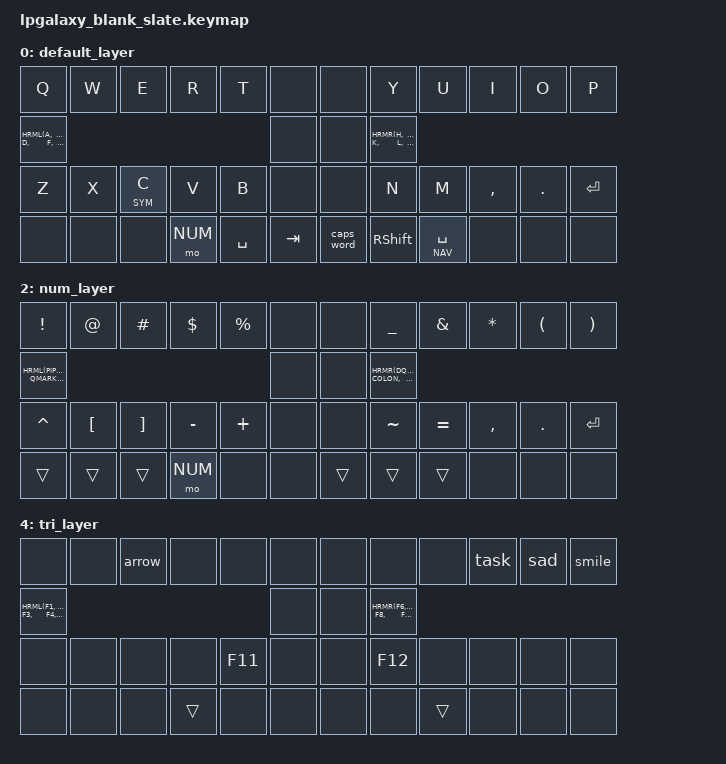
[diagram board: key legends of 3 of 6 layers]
/*
 * Copyright (c) 2022 Pete Johanson
 *
 * SPDX-License-Identifier: MIT
 */

#include <behaviors.dtsi>
#include <dt-bindings/zmk/keys.h>
#include <dt-bindings/zmk/bt.h>
#include <dt-bindings/zmk/outputs.h>
#include <dt-bindings/zmk/pointing.h>
#include "helper.h"

#define DEF 0
#define SYM 1
#define NUM 2
#define NAV 3
#define TRI 4
#define CONF 5

#define XXX &none
#define ___ &trans
#define MEH LC(LA(LSHIFT))

#define QUICK_TAP_MS 175
#define TAPPING_TERM_MS 300
#define REQ_PRIOR_IDLE_MS 200

// Home row mods macro
#define HRML(k1,k2,k3,k4,k5) &hml LSHIFT k1 &hml LGUI k2 &hml LALT k3 &hml LCTRL k4 &hml MEH k5
#define HRMR(k1,k2,k3,k4,k5) &hmr MEH k1 &hmr RCTRL k2  &hmr LALT k3 &hmr RGUI k4 &hmr RSHIFT k5

// Bluetooth
#define BT_SEL_ROW &bt BT_SEL 0 &bt BT_SEL 1 &bt BT_SEL 2 &bt BT_SEL 3
#define BT_SEL_CLR &bt BT_CLR

&caps_word {
    continue-list = <UNDERSCORE MINUS BSPC DOT>;
};

#define KEYS_L 0 1 2 3 4 5 12 13 14 15 16 17 24 25 26 27 28 29   // left-hand keys
#define KEYS_R 6 7 8 9 10 11 18 19 20 21 22 23 30 31 32 33 34 35 // right-hand keys
#define THUMBS 39 40 41 42 43 44           // thumb keys

ZMK_BEHAVIOR(hml, hold_tap,  // left-hand HRMs
    flavor = "balanced";
    tapping-term-ms = <TAPPING_TERM_MS>;
    quick-tap-ms = <QUICK_TAP_MS>;
    require-prior-idle-ms = <REQ_PRIOR_IDLE_MS>;
    hold-trigger-on-release;
    bindings = <&kp>, <&kp>;
    hold-trigger-key-positions = <KEYS_R THUMBS>;
)

ZMK_BEHAVIOR(hmr, hold_tap,  // right-hand HRMs
    flavor = "balanced";
    tapping-term-ms = <TAPPING_TERM_MS>;
    quick-tap-ms = <QUICK_TAP_MS>;
    require-prior-idle-ms = <REQ_PRIOR_IDLE_MS>;
    hold-trigger-on-release;
    bindings = <&kp>, <&kp>;
    hold-trigger-key-positions = <KEYS_L THUMBS>;
)

#undef COMBO_TERM
#define COMBO_TERM 30  // timeout of 40ms (default is 30ms if omitted)
ZMK_COMBO(paswe,        &pasw,          11 12 13, DEF)    // pasw macro on P+A+S
ZMK_COMBO(lockscr,      &kp LG(L),      0 1 2,    DEF)    // Win lock screen by pressing Q W E
ZMK_COMBO(conflayer,    &to CONF,       0 11,     DEF)    // config layer op Q en P
ZMK_COMBO(ctrlspce,     &kp LC(SPACE),  15 20,    DEF)    // runbar op F + J 

// windows sleep macro
ZMK_BEHAVIOR(win_sleep, macro,
    wait-ms = <100>;
    tap-ms = <5>;
    bindings = <&kp LG(X) &kp U &kp S>;
)

ZMK_BEHAVIOR(smile, macro,
    wait-ms = <100>;
    tap-ms = <5>;
    bindings = <&macro_tap &kp COLON &kp MINUS &kp RPAR>;
)

ZMK_BEHAVIOR(pasw, macro,
    wait-ms = <100>;
    tap-ms = <100>;
    bindings = <&macro_tap &kp EXCL &kp P &kp A &kp S &kp W &kp R>;
)
ZMK_BEHAVIOR(sad, macro,
    wait-ms = <100>;
    tap-ms = <5>;
    bindings = <&macro_tap &kp COLON &kp MINUS &kp LPAR>;
)
ZMK_BEHAVIOR(arrow, macro,
    wait-ms = <100>;
    tap-ms = <5>;
    bindings = <&macro_tap &kp MINUS &kp GT>;
)
ZMK_BEHAVIOR(task, macro,
    wait-ms = <100>;
    tap-ms = <5>;
    bindings = <&macro_tap &kp MINUS &kp SPACE &kp LBKT &kp SPACE &kp RBKT &kp SPACE>;
)
ZMK_CONDITIONAL_LAYER (NUM NAV, TRI)

ZMK_LAYER(default_layer,
                &kp Q       &kp W     &kp E      &kp R     &kp T        XXX      XXX        &kp Y       &kp U         &kp I      &kp O      &kp P
                HRML(A,     S,        D,         F,        G)           XXX      XXX        HRMR(H,     J,            K,         L,         BSPC)     
                &kp Z       &kp X     &lt SYM C  &kp V     &kp B        XXX      XXX        &kp N       &kp M         &kp COMMA  &kp DOT    &kp ENTER
                XXX         XXX       XXX        &mo NUM   &kp SPACE    &kp TAB  &caps_word &kp RSHIFT  &lt NAV SPACE XXX        XXX        XXX
)

ZMK_LAYER(sym_layer, 
                ___       ___       ___        ___       ___          XXX      XXX        &kp LBRC    &kp N4        &kp N5     &kp N6     &kp RBRC
                HRML(A,   S,        D,         F,        G)           XXX      XXX        &kp N0      &kp N1        &kp N2     &kp N3     ___
                ___       ___       &lt SYM C  ___       ___          XXX      XXX        &kp DOT     &kp N7        &kp N8     &kp N9     ___
                ___       ___       ___        XXX       ___          XXX      ___        ___         ___           ___        ___        ___
)

ZMK_LAYER(num_layer,
                &kp EXCL    &kp AT    &kp HASH  &kp DOLLAR &kp PERCENT  XXX      XXX       &kp UNDER   &kp AMPS      &kp STAR   &kp LPAR   &kp RPAR
                HRML(PIPE,  BSLH,     FSLH,     QMARK,     GRAVE)       XXX      XXX       HRMR(DQT,   SQT,          COLON,     SEMI,      BSPC)
                &kp CARET   &kp LBKT  &kp RBKT  &kp MINUS  &kp PLUS     XXX      XXX       &kp TILDE   &kp EQUAL     &kp COMMA  &kp DOT    &kp ENTER
                ___         ___       ___       &mo NUM    XXX          XXX      ___       ___         ___           XXX        XXX        XXX
)

ZMK_LAYER(nav_layer,
   	 	        &kp ESC     XXX       XXX       XXX        XXX          XXX      XXX       XXX         XXX           &kp UP     XXX        &kp PAGE_UP
   	            HRML(PIPE,  SEMI,     MINUS,    ENTER,     COMMA)       XXX      XXX       &kp DEL     &kp LEFT      &kp DOWN   &kp RIGHT  &kp BSPC 
   	            XXX         XXX       XXX       XXX        XXX          XXX      XXX       XXX         &kp HOME      XXX        &kp END    &kp PAGE_DOWN
                ___         ___       ___       ___        &kp SPACE    &kp TAB  XXX       XXX         ___           ___        ___        ___
) 

ZMK_LAYER(tri_layer,     
                XXX         XXX       &arrow    XXX        XXX          XXX      XXX    XXX            XXX           &task      &sad       &smile
                HRML(F1,    F2,       F3,       F4,        F5)          XXX      XXX    HRMR(F6,       F7,           F8,        F9,        F10)
                XXX         XXX       XXX       XXX        &kp F11      XXX      XXX    &kp F12        XXX           XXX        XXX        XXX
                XXX         XXX       XXX       ___        XXX          XXX      XXX    XXX            ___           XXX        XXX        XXX
)

ZMK_LAYER(config_layer,     
                &to DEF     XXX       XXX       XXX        XXX          XXX      XXX     XXX           XXX           XXX        XXX        XXX
                BT_SEL_ROW                                 XXX          XXX      XXX     XXX           XXX           XXX        XXX        BT_SEL_CLR
                XXX         XXX       XXX       XXX        XXX          XXX      XXX     XXX           XXX           XXX        XXX        XXX
                XXX         XXX       XXX       &kp C      &kp O        XXX      XXX     &kp N         &kp F         XXX        XXX        XXX
)

    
